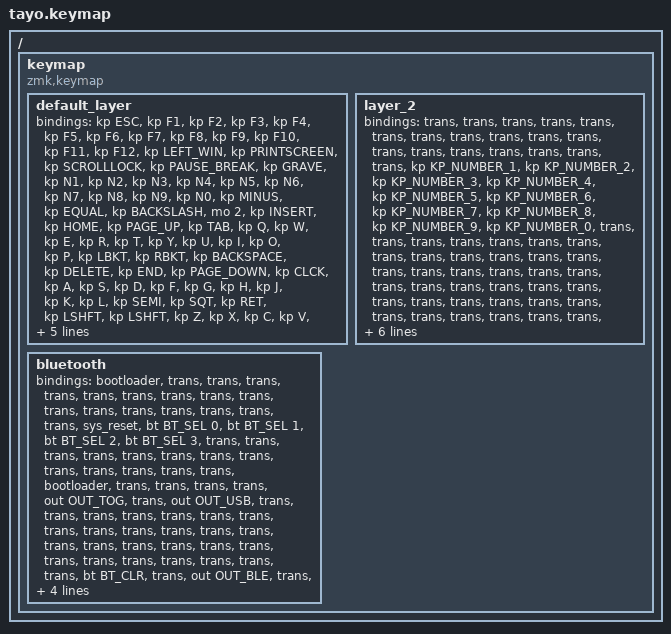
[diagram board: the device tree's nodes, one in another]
/*
 * Copyright (c) 2021 Nick Winans
 *
 * SPDX-License-Identifier: MIT
 */

#include <behaviors.dtsi>
#include <dt-bindings/zmk/bt.h>
#include <dt-bindings/zmk/keys.h>
#include <dt-bindings/zmk/outputs.h>

/ {
    keymap {
        compatible = "zmk,keymap";

        default_layer {
            bindings = <
&kp ESC  &kp F1  &kp F2  &kp F3  &kp F4  &kp F5  &kp F6  &kp F7  &kp F8  &kp F9  &kp F10  &kp F11  &kp F12  &kp LEFT_WIN  &kp PRINTSCREEN  &kp SCROLLLOCK  &kp PAUSE_BREAK  &kp GRAVE  &kp N1  &kp N2  &kp N3  &kp N4  &kp N5  &kp N6  &kp N7  &kp N8  &kp N9  &kp N0  &kp MINUS  &kp EQUAL  &kp BACKSLASH  &mo 2  &kp INSERT  &kp HOME  &kp PAGE_UP  &kp TAB  &kp Q  &kp W  &kp E  &kp R  &kp T  &kp Y  &kp U  &kp I  &kp O  &kp P  &kp LBKT  &kp RBKT  &kp BACKSPACE  &kp DELETE  &kp END  &kp PAGE_DOWN  &kp CLCK  &kp A  &kp S  &kp D  &kp F  &kp G  &kp H  &kp J  &kp K  &kp L  &kp SEMI  &kp SQT  &kp RET  &kp LSHFT  &kp LSHFT  &kp Z  &kp X  &kp C  &kp V  &kp B  &kp N  &kp M  &kp COMMA  &kp DOT  &kp FSLH  &kp RSHFT  &mo 2  &trans  &kp UP  &trans  &kp LCTRL  &trans  &kp LEFT_ALT  &kp SPACE  &none  &mo 1  &trans  &kp RCTRL  &kp LEFT  &kp DOWN  &kp RIGHT
            >;
        };

        layer_2 {
            bindings = <
&trans  &trans  &trans  &trans  &trans  &trans  &trans  &trans  &trans  &trans  &trans  &trans  &trans  &trans  &trans  &trans  &trans  &trans  &kp KP_NUMBER_1  &kp KP_NUMBER_2  &kp KP_NUMBER_3  &kp KP_NUMBER_4  &kp KP_NUMBER_5  &kp KP_NUMBER_6  &kp KP_NUMBER_7  &kp KP_NUMBER_8  &kp KP_NUMBER_9  &kp KP_NUMBER_0  &trans  &trans  &trans  &trans  &trans  &trans  &trans  &trans  &trans  &trans  &trans  &trans  &trans  &trans  &trans  &trans  &trans  &trans  &trans  &trans  &trans  &trans  &trans  &trans  &trans  &trans  &trans  &trans  &trans  &trans  &trans  &trans  &trans  &trans  &trans  &trans  &trans  &trans  &trans  &trans  &trans  &trans  &trans  &trans  &trans  &trans  &trans  &trans  &trans  &trans  &trans  &trans  &kp C_VOLUME_UP  &trans  &trans  &trans  &trans  &trans  &trans  &trans  &trans  &trans  &kp C_PAUSE  &kp C_VOL_DN  &kp C_PLAY
            >;
        };

        bluetooth {
            bindings = <
&bootloader  &trans  &trans  &trans  &trans  &trans  &trans  &trans  &trans  &trans  &trans  &trans  &trans  &trans  &trans  &trans  &trans  &sys_reset  &bt BT_SEL 0  &bt BT_SEL 1  &bt BT_SEL 2  &bt BT_SEL 3  &trans  &trans  &trans  &trans  &trans  &trans  &trans  &trans  &trans  &trans  &trans  &trans  &trans  &bootloader  &trans  &trans  &trans  &trans  &out OUT_TOG  &trans  &out OUT_USB  &trans  &trans  &trans  &trans  &trans  &trans  &trans  &trans  &trans  &trans  &trans  &trans  &trans  &trans  &trans  &trans  &trans  &trans  &trans  &trans  &trans  &trans  &trans  &trans  &trans  &trans  &bt BT_CLR  &trans  &out OUT_BLE  &trans  &trans  &trans  &trans  &trans  &trans  &trans  &trans  &trans  &trans  &trans  &trans  &trans  &trans  &trans  &trans  &trans  &trans  &trans  &trans  &trans
            >;
        };
    };
};
